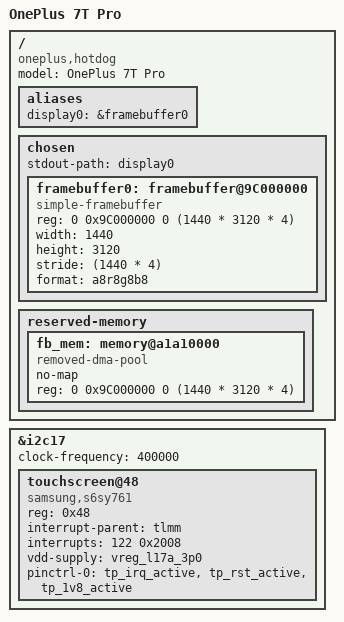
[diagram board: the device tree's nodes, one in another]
// SPDX-License-Identifier: BSD-3-Clause
/*
 * Devicetree for the OnePlus 7T Pro (hotdog), including the McLaren Edition
 * (HD1910/HD1911/HD1913). ucrom mainline fallback.
 *
 * Derived from sm8150-oneplus-guacamole.dts (OnePlus 7 Pro,
 * Copyright (c) 2021, Caleb Connolly <caleb@connolly.tech>). The 7T Pro keeps
 * the 7 Pro's board design; each value below was cross-checked against the
 * OnePlus/LineageOS vendor device tree for project 19801 (7T Pro):
 *   - touch: Samsung S6SY761 ("sec-s6sy761"), i2c17 (qupv3_se17) @0x48,
 *     IRQ tlmm 122 (0x2008), reset tlmm 54, vdd pm8150 L17 (3.008 V),
 *     panel/display coords 1439x3119  (19801/sm8150-oem.dtsi)
 *   - panel: 1440x3120 (19801 touchpanel,display-coords; LineageOS hotdog
 *     density 560)
 *   - bootloader splash framebuffer: 0x9c000000, size 0x2400000
 *     (qcom/sm8150.dtsi cont_splash_region)
 *   - buttons (power, volume): unchanged from sm8150-oneplus-common.dtsi,
 *     same pm8150 wiring as the 7 Pro (vendor 18821 vs 19801 sm8150-oem.dtsi)
 */

/dts-v1/;

#include <dt-bindings/regulator/qcom,rpmh-regulator.h>
#include <dt-bindings/gpio/gpio.h>
#include "sm8150-oneplus-common.dtsi"

/ {
	model = "OnePlus 7T Pro";
	compatible = "oneplus,hotdog", "oneplus,oneplus7", "qcom,sm8150";

	aliases {
		display0 = &framebuffer0;
	};

	chosen {
		#address-cells = <2>;
		#size-cells = <2>;
		ranges;
		stdout-path = "display0";

		/*
		 * hack: Use framebuffer setup by the bootloader for simplefb.
		 * the address is taken from the bootloader config (strings xbl.img | grep "Display Reserved")
		 */
		framebuffer0: framebuffer@9C000000 {
			compatible = "simple-framebuffer";
			reg = <0 0x9C000000 0 (1440 * 3120 * 4)>;
			width = <1440>;
			height = <3120>;
			stride = <(1440 * 4)>;
			format = "a8r8g8b8";
			status = "okay";

		};
	};

	reserved-memory {
	// hack: Bootloader framebuffer memory region
		fb_mem: memory@a1a10000 {
			compatible = "removed-dma-pool";
			no-map;
			reg = <0 0x9C000000 0 (1440 * 3120 * 4)>;
		};
	};
};

&i2c17 {
	status = "okay";
	clock-frequency = <400000>;

	touchscreen@48 {
		compatible = "samsung,s6sy761";
		status = "okay";
		reg = <0x48>;
		interrupt-parent = <&tlmm>;
		interrupts = <122 0x2008>;
		vdd-supply = <&vreg_l17a_3p0>;

		pinctrl-names = "default";
		pinctrl-0 = <&tp_irq_active &tp_rst_active &tp_1v8_active>;
	};
};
